# MB9BF16xM register map
Vendor: Cypress; File version: 2.1
CPU: CM4 r0p1, little endian, MPU, FPU, 4 interrupt priority bits
Registers are 32-bit, read-write, reset 0x0 unless marked. A register's access mark holds for its fields unless they carry their own. Offsets are from the block's base; [hi:lo] are bit positions; {n}, {i} and the like mark numbered series.

## ADC0 — ADC0 Registers
Base 0x40027000
Same registers: ADC1 0x40027100, ADC2 0x40027200
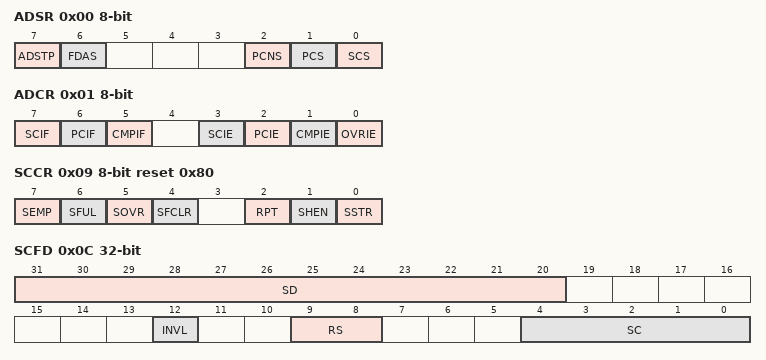
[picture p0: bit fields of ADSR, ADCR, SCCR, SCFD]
0x00 ADSR 8-bit — A/D Status Register [BHW]
  [7] ADSTP — A/D conversion forced stop bit
  [6] FDAS — FIFO data placement selection bit
  [2] PCNS ro — Priority conversion pending flag
  [1] PCS ro — Priority conversion status flag
  [0] SCS ro — Scan conversion status flag
0x01 ADCR 8-bit — A/D Control Register [BHW]
  [7] SCIF — Scan conversion interrupt request bit
  [6] PCIF — Priority conversion interrupt request bit
  [5] CMPIF — Conversion result comparison interrupt request bit
  [3] SCIE — Scan conversion interrupt enable bit
  [2] PCIE — Priority conversion interrupt enable bit
  [1] CMPIE — Conversion result comparison interrupt enable bit
  [0] OVRIE — FIFO overrun interrupt enable bit
0x08 SFNS 8-bit — Scan Conversion FIFO Stage Count Setup Register [BHW]
  [3:0] SFS — Scan conversion FIFO stage count setting bit
0x09 SCCR 8-bit reset 0x80 — Scan Conversion Control Register [BHW]
  [7] SEMP ro — Scan conversion FIFO empty bit
  [6] SFUL ro — Scan conversion FIFO full bit
  [5] SOVR — Scan conversion overrun flag
  [4] SFCLR — Scan conversion FIFO clear bit
  [2] RPT — Scan conversion repeat bit
  [1] SHEN — Scan conversion timer start enable bit
  [0] SSTR — Scan conversion start bit
0x0C SCFD ro (reset mask 0x1000) (alternate view of SCFD_FDAS1) — Scan Conversion FIFO Data Register for ADSR.FDAS=0 [BHW]
  [31:20] SD — Scan conversion result
  [12] INVL — A/D conversion result disable bit
  [9:8] RS — Scan conversion start factor
  [4:0] SC — Conversion input channel bits
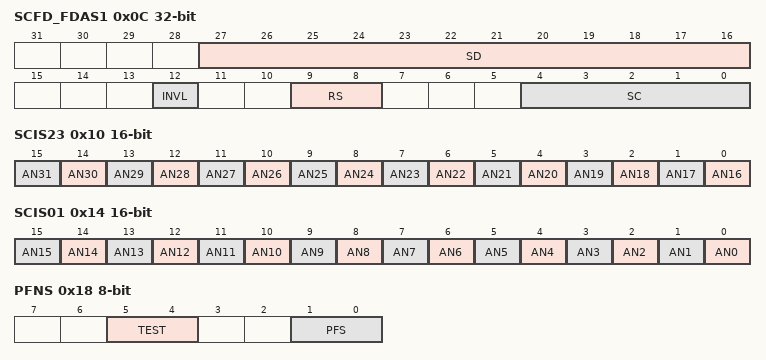
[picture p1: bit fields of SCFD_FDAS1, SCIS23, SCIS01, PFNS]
0x0C SCFD_FDAS1 ro (reset mask 0x1000) (alternate view of SCFD) — Scan Conversion FIFO Data Register for ADSR.FDAS=1 [BHW]
  [27:16] SD — Scan conversion result
  [12] INVL — A/D conversion result disable bit
  [9:8] RS — Scan conversion start factor
  [4:0] SC — Conversion input channel bits
0x10 SCIS23 16-bit — Scan Conversion Input Selection Register 2 and 3 [BHW]
  [n-16] AN{n} (n=16..31) — Bit{n-16} of SCIS23
0x14 SCIS01 16-bit — Scan Conversion Input Selection Register 1 [BHW]
  [n] AN{n} (n=0..15) — Bit{n} of SCIS01
0x18 PFNS 8-bit (reset mask 0x3) — Priority Conversion FIFO Stage Count Setup Register [BHW]
  [5:4] TEST ro — Test bits
  [1:0] PFS — Priority conversion FIFO stage count setting bits
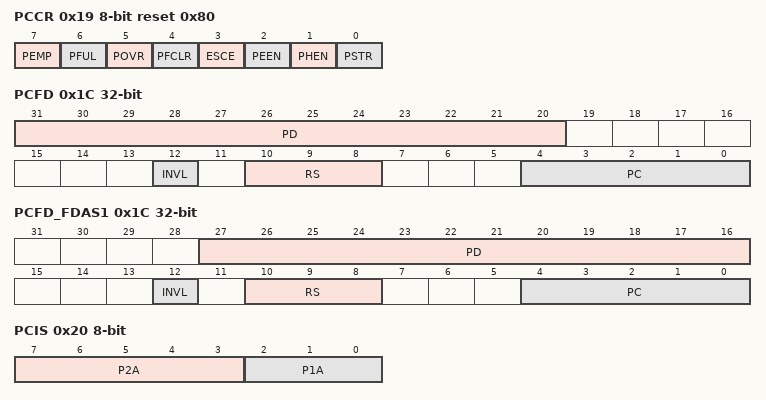
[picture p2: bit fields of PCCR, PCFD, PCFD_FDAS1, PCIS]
0x19 PCCR 8-bit reset 0x80 — Priority Conversion Control Register [BHW]
  [7] PEMP ro — Priority conversion FIFO empty bit
  [6] PFUL ro — Priority conversion FIFO full bit
  [5] POVR — Priority conversion overrun flag
  [4] PFCLR — Priority conversion FIFO clear bit
  [3] ESCE — External trigger analog input selection bit
  [2] PEEN — Priority conversion external start enable bit
  [1] PHEN — Priority conversion timer start enable bit
  [0] PSTR — Priority conversion start bit
0x1C PCFD ro (alternate view of PCFD_FDAS1) — Priority Conversion FIFO Data Register for ADSR.FDAS=0 [BHW]
  [31:20] PD — Priority conversion result
  [12] INVL — A/D conversion result disable bit
  [10:8] RS — Scan conversion start factor
  [4:0] PC — Conversion input channel bits
0x1C PCFD_FDAS1 ro (alternate view of PCFD) — Priority Conversion FIFO Data Register for ADSR.FDAS=1 [BHW]
  [27:16] PD — Priority conversion result
  [12] INVL — A/D conversion result disable bit
  [10:8] RS — Scan conversion start factor
  [4:0] PC — Conversion input channel bits
0x20 PCIS 8-bit — Priority Conversion Input Selection Register [BHW]
  [7:3] P2A — Priority level 2 analog input selection
  [2:0] P1A — Priority level 1 analog input selection
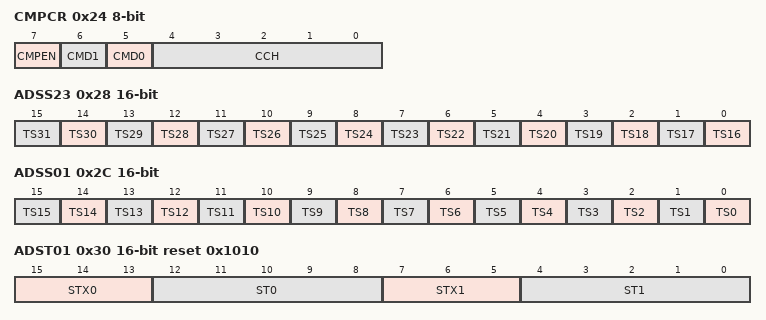
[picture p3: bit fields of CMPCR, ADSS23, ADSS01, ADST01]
0x24 CMPCR 8-bit — A/D Comparison Control Register [BHW]
  [7] CMPEN — Conversion result comparison function operation enable bit
  [6] CMD1 — Comparison mode 1
  [5] CMD0 — Comparison mode 0
  [4:0] CCH — Comparison target analog input channel
0x26 CMPD 16-bit — A/D Comparison Value Setup Register [BHW]
  [15:6] CMAD — A/D conversion result value setting bits
0x28 ADSS23 16-bit — Sampling Time Selection Register 2 and 3 [BHW]
  [n-16] TS{n} (n=16..31) — Bit{n-16} of ADSS23
0x2C ADSS01 16-bit — Sampling Time Selection Register 0 and 1 [BHW]
  [n] TS{n} (n=0..15) — Bit{n} of ADSS01
0x30 ADST01 16-bit reset 0x1010 — Sampling Time Setup Register [BHW]
  [15:13] STX0 — Sampling time N times setting bits
  [12:8] ST0 — Sampling time setting bits
  [7:5] STX1 — Sampling time N times setting bits
  [4:0] ST1 — Sampling time setting bits
0x34 ADCT 8-bit reset 0x7 — Frequency Division Ratio Setup Register [BHW]
  [7:0] CT — Frequency division ratio setting bits
0x38 PRTSL 8-bit — Priority Conversion Timer Trigger Selection Register [BHW]
  [3:0] PRTSL — Priority conversion timer trigger selection bit
0x39 SCTSL 8-bit — Scan Conversion Timer Trigger Selection Register [BHW]
  [3:0] SCTSL — Scan conversion timer trigger selection bit
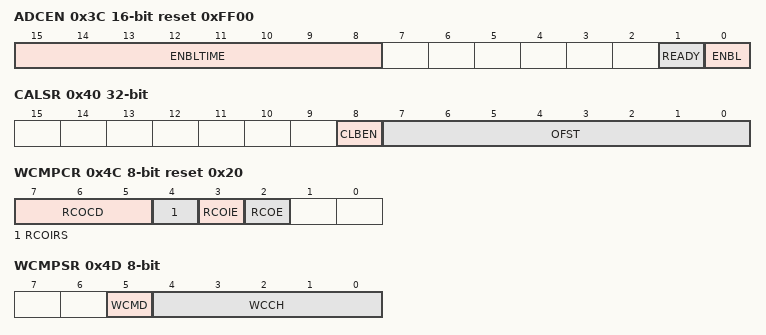
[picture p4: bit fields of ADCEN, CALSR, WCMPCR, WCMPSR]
0x3C ADCEN 16-bit reset 0xFF00 — A/D Operation Enable Setup Register [BHW]
  [15:8] ENBLTIME — Operation enable state transition cycle selection bits
  [1] READY ro — A/D operation enable state bit
  [0] ENBL — A/D operation enable bit
0x40 CALSR — Calibration Setting Register [BHW]
  [8] CLBEN — Calibration permission bit
  [7:0] OFST — Offset calibration value setting bits
0x44 WCMRCOT 8-bit — Range Comparison Threshold Excess Flag Register [BHW]
  [0] RCOOF — Threshold excess flag bit
0x48 WCMRCIF 8-bit — Range Comparison Flag Register [BHW]
  [0] RCINT — Range comparison interrupt factor flag
0x4C WCMPCR 8-bit reset 0x20 — Range Comparison Control Register [BHW]
  [7:5] RCOCD — Continuous detection specification count/state indication bits
  [4] RCOIRS — Selection bit of within-range and out-of- range confirmation
  [3] RCOIE — Range comparison interrupt request enable bit
  [2] RCOE — Range comparison execution enable bit
0x4D WCMPSR 8-bit — Range Comparison Channel Select Register [BHW]
  [5] WCMD — Comparison mode select bit
  [4:0] WCCH — Comparison target analog input channel
0x50 WCMPDL 16-bit — Lower Limit Threshold Setup Register [BHW]
  [15:6] CMLD — Lower limit threshold bits
0x52 WCMPDH 16-bit — Upper Limit Setup Register [BHW]
  [15:6] CMHD — Upper limit threshold bits

## Notices in the file
Copyright (C) 2013-2016, Cypress Semiconductor Corporation or a
subsidiary of Cypress Semiconductor Corporation.  All rights reserved.
This software, including source code, documentation and related
materials ("Software"), is owned by Cypress Semiconductor Corporation or
one of its subsidiaries ("Cypress") and is protected by and subject to
worldwide patent protection (United States and foreign), United States
copyright laws and international treaty provisions. Therefore, you may use
this Software only as provided in the license agreement accompanying the
software package from which you obtained this Software ("EULA").
If no EULA applies, Cypress hereby grants you a personal, non-exclusive,
non-transferable license to copy, modify, and compile the
Software source code solely for use in connection with Cypress's
integrated circuit products.  Any reproduction, modification, translation,
compilation, or representation of this Software except as specified
above is prohibited without the express written permission of Cypress.
Disclaimer: THIS SOFTWARE IS PROVIDED AS-IS, WITH NO
WARRANTY OF ANY KIND, EXPRESS OR IMPLIED, INCLUDING,
BUT NOT LIMITED TO, NONINFRINGEMENT, IMPLIED
WARRANTIES OF MERCHANTABILITY AND FITNESS FOR A
PARTICULAR PURPOSE. Cypress reserves the right to make
changes to the Software without notice. Cypress does not assume any
liability arising out of the application or use of the Software or any
product or circuit described in the Software. Cypress does not
authorize its products for use in any products where a malfunction or
failure of the Cypress product may reasonably be expected to result in
significant property damage, injury or death ("High Risk Product"). By
including Cypress's product in a High Risk Product, the manufacturer
of such system or application assumes all risk of such use and in doing
so agrees to indemnify Cypress against all liability.
